VERSION "1.1"

NS_ :

BS_:

BU_: VBOX_II

BO_ 24 VBOX_5: 8 VBOX_II
 SG_ Trig_Vel_mph : 55|16@0+ (0.0115078,0) [0|754.163673] "mph" VBOX_II
 SG_ Trig_Vel_kph : 55|16@0+ (0.01852,0) [0|1213.7082] "km/h" VBOX_II
 SG_ Trig_time : 39|16@0+ (0.01,0) [0|655.35] "Secs" VBOX_II
 SG_ Distance : 7|32@0+ (7.8125E-005,0) [0|335544] "Metres" VBOX_II

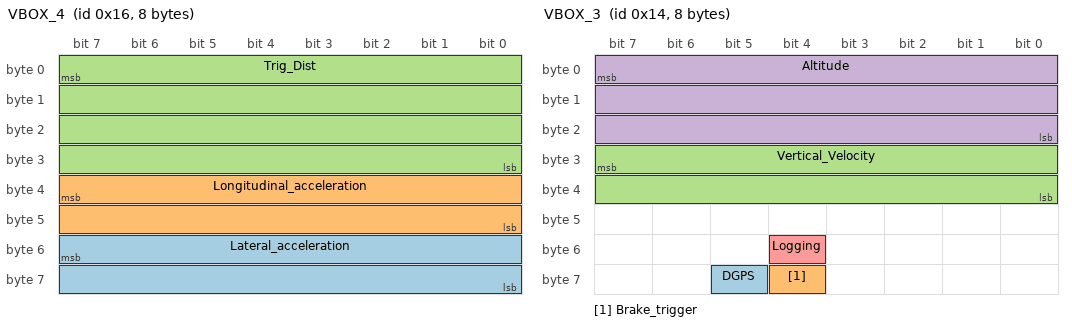
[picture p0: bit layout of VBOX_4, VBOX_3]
BO_ 22 VBOX_4: 8 VBOX_II
 SG_ Lateral_acceleration : 55|16@0- (0.01,0) [-327.68|327.67] "G"  VBOX_II
 SG_ Longitudinal_acceleration : 39|16@0- (0.01,0) [-327.68|327.67] "G"  VBOX_II
 SG_ Trig_Dist : 7|32@0+ (7.8125E-005,0) [0|335544] "metres"  VBOX_II

BO_ 20 VBOX_3: 8 VBOX_II
 SG_ DGPS : 61|1@0+ (1,0) [0|0] "On"  VBOX_II
 SG_ Brake_trigger : 60|1@0+ (1,0) [0|0] "On"  VBOX_II
 SG_ Vertical_Velocity : 31|16@0- (0.01,0) [0|655.36] "m/s"  VBOX_II
 SG_ Altitude : 7|24@0- (0.01,0) [0|42949700] "metres"  VBOX_II
 SG_ Logging : 52|1@0+ (1,0) [0|0] "" VBOX_II

BO_ 18 VBOX_2: 8 VBOX_II
 SG_ Heading : 55|16@0+ (0.01,0) [0|359.99] "Degrees"  VBOX_II
 SG_ Velocity_kmh : 39|16@0+ (0.018519984,0) [0|1213.7082] "km/h"  VBOX_II
 SG_ Velocity_mph : 39|16@0+ (0.0115078,0) [0|754.163673] "mph"  VBOX_II
 SG_ East_West : 7|1@0+ (1,0) [0|0] "East"  VBOX_II
 SG_ East_West_enum : 7|1@0+ (1,0) [0|0] ""  VBOX_II
 SG_ Longitude : 7|32@0- (1E-005,0) [-21474.83648|21474.83647] "Minutes" VBOX_II
 SG_ Longitude_deg : 6|31@0+ (1E-005,0) [0|180] "Degrees"  VBOX_II

BO_ 16 VBOX_1: 8 VBOX_II
 SG_ North_South : 39|1@0+ (1,0) [0|0] "South"  VBOX_II
 SG_ North_South_enum : 39|1@0+ (1,0) [0|0] ""  VBOX_II
 SG_ Latitude : 39|32@0- (1E-005,0) [-21474.83648|21474.83647] "Minutes" VBOX_II
 SG_ Latitude_deg : 38|31@0+ (1E-005,0) [0|90] "Degrees"  VBOX_II
 SG_ Time : 15|24@0+ (1,0) [0|0] "UTC"  VBOX_II
 SG_ Sats : 7|8@0+ (1,0) [0|12] "Sats"  VBOX_II

CM_ "Racelogic VBOX II";
CM_ BU_ VBOX_II "Racelogic VBOX II";
CM_ BO_ 16 "VBOX Message 1";
CM_ BO_ 18 "VBOX Message 2";
CM_ BO_ 20 "VBOX Message 3";
CM_ BO_ 22 "VBOX Message 4";
CM_ BO_ 24 "VBOX Message 5";
CM_ SG_ 22 Lateral_acceleration "Lateral acceleration in G";
CM_ SG_ 22 Longitudinal_acceleration "Longitudinal acceleration in G";
CM_ SG_ 22 Trig_Dist "Distance in metres";
CM_ SG_ 20 DGPS "DGPS lock status

1 = DGPS active
0 = DGPS not active";
CM_ SG_ 20 Brake_trigger "Brake trigger switch status";
CM_ SG_ 20 Vertical_Velocity "Vertical velocityin metres/sec";
CM_ SG_ 20 Altitude "Altitude in metres

ref WGS84
";
CM_ SG_ 18 Heading "Heading in degrees";
CM_ SG_ 18 Velocity_kmh "Velocity (km/h)";
CM_ SG_ 18 Velocity_mph "Velocity (mph)";
CM_ SG_ 18 East_West "Hemisphere

West = 0
East = 1
";
CM_ SG_ 18 Longitude "Longitude
DDMM.MMMMM

Example 5882246 = 0 Degrees 58.82246 minutes";
CM_ SG_ 16 North_South "Hemisphere
North = 0
South = 1";
CM_ SG_ 16 Latitude "Latitude DDMM.MMMMM
Example 515924579 = 51 Degrees, 59.24579 Minutes";
CM_ SG_ 16 Time "Time UTC";
CM_ SG_ 16 Sats "Satelites in view";
VAL_ 18 East_West_enum 0 "West" 1 "East" ;
VAL_ 16 North_South_enum 0 "North" 1 "South" ;
